AUTOSAR XML (schema 4-2-1)
package /DataType
  base type my_uint8: category=FIXED_LENGTH, base-type-size=8, base-type-encoding=NONE, native-declaration=unsigned char
  impl type my_uint8: category=VALUE, base-type=my_uint8, range phys 0..255, raw 0..255
  impl type CAN_FRAME: category=ARRAY
    element Array_Element: category=VALUE, array-size=8, array-size-handling=ALL-INDICES-SAME-ARRAY-SIZE, array-size-semantics=FIXED-SIZE, base-type=my_uint8, range phys 0..255, raw 0..255
package /Interfacing
  sender receiver interface SRI_CAN_Frame
    data CAN_Frame: type=CAN_FRAME, init-value=[0]
  sender receiver interface SRI_LED_Warning
    data LED_Warning: type=my_uint8, init-value=0
  client server interface CSI_Call_Subsystem
    operation Call_Subsystem: possible-error=[E_NOT_OK, E_OK]
      arg CAN_Frame: type=CAN_FRAME, direction=IN
    error E_NOT_OK: error-code=0
    error E_OK: error-code=1
  sender receiver interface SRI_LCD_Warning
    data LCD_Warning: type=my_uint8, init-value=0
  sender receiver interface SRI_Motor_Speed
    data Motor_Speed: type=my_uint8, init-value=0
package /SWCs
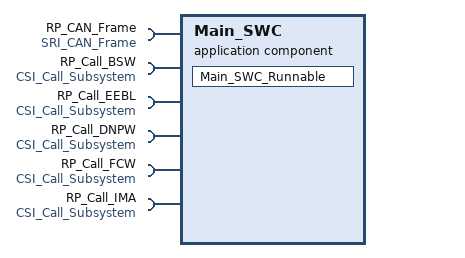
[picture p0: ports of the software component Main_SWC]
  application sw component type Main_SWC
    6 x require port:
      RP_CAN_Frame: required-interface=SRI_CAN_Frame
      RP_Call_BSW: required-interface=CSI_Call_Subsystem
      RP_Call_EEBL: required-interface=CSI_Call_Subsystem
      RP_Call_DNPW: required-interface=CSI_Call_Subsystem
      RP_Call_FCW: required-interface=CSI_Call_Subsystem
      RP_Call_IMA: required-interface=CSI_Call_Subsystem
    behavior IB_Main_SWC
      data received event Frame_Received_Event: start-on-event=Main_SWC_Runnable, data=CAN_Frame
      runnable Main_SWC_Runnable: symbol=Main_SWC
        data-read-access:
          access DR_Access: accessed-variable=RP_CAN_Frame.CAN_Frame
        5 x sync call:
          SYN_ServerCallDNPW: operation=RP_Call_DNPW.Call_Subsystem
          SYN_ServerCallFCW: operation=RP_Call_FCW.Call_Subsystem
          SYN_ServerCallBSW: operation=RP_Call_BSW.Call_Subsystem
          SYN_ServerCallIMA: operation=RP_Call_IMA.Call_Subsystem
          SYN_ServerCallEEBL: operation=RP_Call_EEBL.Call_Subsystem
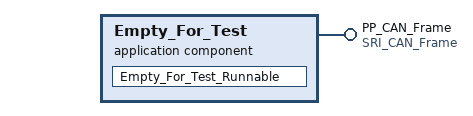
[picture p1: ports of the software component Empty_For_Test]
  application sw component type Empty_For_Test
    provide port PP_CAN_Frame: provided-interface=SRI_CAN_Frame
    behavior IB_Empty_For_Test
      runnable Empty_For_Test_Runnable: symbol=Empty_For_Test
        data-write-access:
          access DW_Access: accessed-variable=PP_CAN_Frame.CAN_Frame
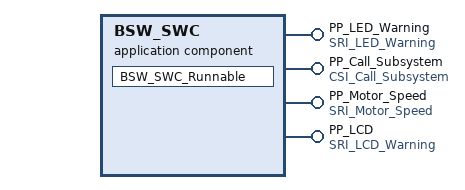
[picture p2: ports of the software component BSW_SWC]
  application sw component type BSW_SWC
    4 x provide port:
      PP_LED_Warning: provided-interface=SRI_LED_Warning
      PP_Call_Subsystem: provided-interface=CSI_Call_Subsystem
      PP_Motor_Speed: provided-interface=SRI_Motor_Speed
      PP_LCD: provided-interface=SRI_LCD_Warning
    behavior IB_BSW_SWC
      operation invoked event OIE_BSW_Runnable: start-on-event=BSW_SWC_Runnable, operation=PP_Call_Subsystem.Call_Subsystem
      runnable BSW_SWC_Runnable: symbol=BSW_SWC
        data-write-access:
          access DW_LED_Warning: accessed-variable=PP_LED_Warning.LED_Warning
          access DW_Motor_Speed: accessed-variable=PP_Motor_Speed.Motor_Speed
          access DW_LCD: accessed-variable=PP_LCD.LCD_Warning
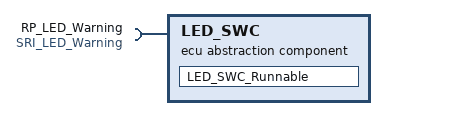
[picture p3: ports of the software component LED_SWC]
  ecu abstraction sw component type LED_SWC
    require port RP_LED_Warning: required-interface=SRI_LED_Warning
    behavior IB_LED_SWC
      data received event LED_Warning_Received_Event: start-on-event=LED_SWC_Runnable, data=LED_Warning
      runnable LED_SWC_Runnable: symbol=LED_SWC
        data-read-access:
          access DR_LED_Warning: accessed-variable=RP_LED_Warning.LED_Warning
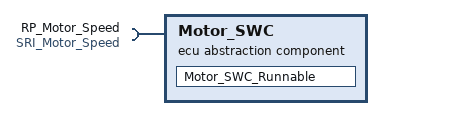
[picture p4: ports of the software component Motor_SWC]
  ecu abstraction sw component type Motor_SWC
    require port RP_Motor_Speed: required-interface=SRI_Motor_Speed
    behavior IB_Motor_Speed
      data received event Motor_Speed_Received_Event: start-on-event=Motor_SWC_Runnable, data=Motor_Speed
      runnable Motor_SWC_Runnable: symbol=Motor_SWC
        data-read-access:
          access DR_Motor_Speed: accessed-variable=RP_Motor_Speed.Motor_Speed
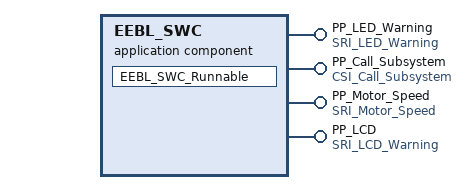
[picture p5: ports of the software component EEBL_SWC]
  application sw component type EEBL_SWC
    4 x provide port:
      PP_LED_Warning: provided-interface=SRI_LED_Warning
      PP_Call_Subsystem: provided-interface=CSI_Call_Subsystem
      PP_Motor_Speed: provided-interface=SRI_Motor_Speed
      PP_LCD: provided-interface=SRI_LCD_Warning
    behavior IB_EEBL_SWC
      operation invoked event OIE_EEBL_Runnable: start-on-event=EEBL_SWC_Runnable, operation=PP_Call_Subsystem.Call_Subsystem
      runnable EEBL_SWC_Runnable: symbol=BSW_SWC
        data-write-access:
          access DW_LED_Warning: accessed-variable=PP_LED_Warning.LED_Warning
          access DW_Motor_Speed: accessed-variable=PP_Motor_Speed.Motor_Speed
          access DW_LCD: accessed-variable=PP_LCD.LCD_Warning
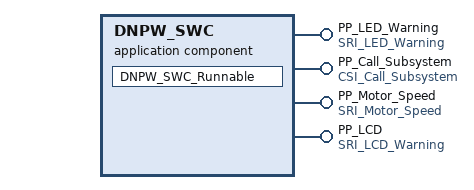
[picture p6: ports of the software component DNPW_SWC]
  application sw component type DNPW_SWC
    4 x provide port:
      PP_LED_Warning: provided-interface=SRI_LED_Warning
      PP_Call_Subsystem: provided-interface=CSI_Call_Subsystem
      PP_Motor_Speed: provided-interface=SRI_Motor_Speed
      PP_LCD: provided-interface=SRI_LCD_Warning
    behavior IB_DNPW_SWC
      operation invoked event OIE_DNPW_Runnable: start-on-event=DNPW_SWC_Runnable, operation=PP_Call_Subsystem.Call_Subsystem
      runnable DNPW_SWC_Runnable: symbol=DNPW_SWC
        data-write-access:
          access DW_LED_Warning: accessed-variable=PP_LED_Warning.LED_Warning
          access DW_Motor_Speed: accessed-variable=PP_Motor_Speed.Motor_Speed
          access DW_LCD: accessed-variable=PP_LCD.LCD_Warning
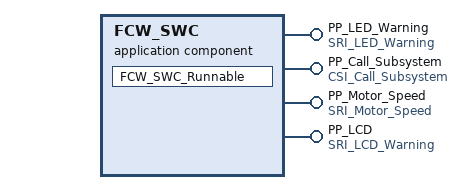
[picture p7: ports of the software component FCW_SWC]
  application sw component type FCW_SWC
    4 x provide port:
      PP_LED_Warning: provided-interface=SRI_LED_Warning
      PP_Call_Subsystem: provided-interface=CSI_Call_Subsystem
      PP_Motor_Speed: provided-interface=SRI_Motor_Speed
      PP_LCD: provided-interface=SRI_LCD_Warning
    behavior IB_FCW_SWC
      operation invoked event OIE_FCW_Runnable: start-on-event=FCW_SWC_Runnable, operation=PP_Call_Subsystem.Call_Subsystem
      runnable FCW_SWC_Runnable: symbol=FCW_SWC
        data-write-access:
          access DW_LED_Warning: accessed-variable=PP_LED_Warning.LED_Warning
          access DW_Motor_Speed: accessed-variable=PP_Motor_Speed.Motor_Speed
          access DW_LCD: accessed-variable=PP_LCD.LCD_Warning
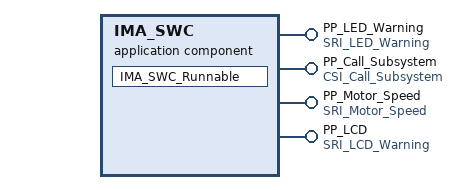
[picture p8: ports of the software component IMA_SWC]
  application sw component type IMA_SWC
    4 x provide port:
      PP_LED_Warning: provided-interface=SRI_LED_Warning
      PP_Call_Subsystem: provided-interface=CSI_Call_Subsystem
      PP_Motor_Speed: provided-interface=SRI_Motor_Speed
      PP_LCD: provided-interface=SRI_LCD_Warning
    behavior IB_IMA_SWC
      operation invoked event OIE_IMA_Runnable: start-on-event=IMA_SWC_Runnable, operation=PP_Call_Subsystem.Call_Subsystem
      runnable IMA_SWC_Runnable: symbol=IMA_SWC
        data-write-access:
          access DW_LED_Warning: accessed-variable=PP_LED_Warning.LED_Warning
          access DW_Motor_Speed: accessed-variable=PP_Motor_Speed.Motor_Speed
          access DW_LCD: accessed-variable=PP_LCD.LCD_Warning
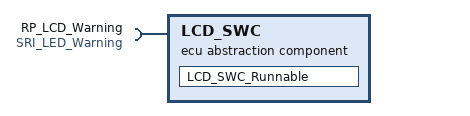
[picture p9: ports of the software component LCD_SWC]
  ecu abstraction sw component type LCD_SWC
    require port RP_LCD_Warning: required-interface=SRI_LED_Warning
    behavior IB_LCD_SWC
      data received event LCD_Warning_Received_Event: start-on-event=LCD_SWC_Runnable, data=LCD_Warning
      runnable LCD_SWC_Runnable: symbol=LCD_SWC
        data-read-access:
          access DR_LCD_Warning: accessed-variable=RP_LCD_Warning.LCD_Warning
package /Composition
  composition sw component type Composition_SWC
    10 x component:
      Main_SWC: type=Main_SWC
      Empty_For_Test: type=Empty_For_Test
      LED_SWC: type=LED_SWC
      BSW_SWC: type=BSW_SWC
      Motor_SWC: type=Motor_SWC
      EEBL_SWC: type=EEBL_SWC
      DNPW_SWC: type=DNPW_SWC
      FCW_SWC: type=FCW_SWC
      IMA_SWC: type=IMA_SWC
      LCD_SWC: type=LCD_SWC
    connect Empty_For_Test.PP_CAN_Frame -> Main_SWC.RP_CAN_Frame
    connect BSW_SWC.PP_Call_Subsystem -> Main_SWC.RP_Call_BSW
    connect EEBL_SWC.PP_Call_Subsystem -> Main_SWC.RP_Call_EEBL
    connect DNPW_SWC.PP_Call_Subsystem -> Main_SWC.RP_Call_DNPW
    connect FCW_SWC.PP_Call_Subsystem -> Main_SWC.RP_Call_FCW
    connect IMA_SWC.PP_Call_Subsystem -> Main_SWC.RP_Call_IMA
    connect BSW_SWC.PP_LCD -> LCD_SWC.RP_LCD_Warning
    connect FCW_SWC.PP_LCD -> LCD_SWC.RP_LCD_Warning
    connect IMA_SWC.PP_LCD -> LCD_SWC.RP_LCD_Warning
    connect DNPW_SWC.PP_LCD -> LCD_SWC.RP_LCD_Warning
    connect EEBL_SWC.PP_LCD -> LCD_SWC.RP_LCD_Warning
    connect BSW_SWC.PP_LED_Warning -> LED_SWC.RP_LED_Warning
    connect FCW_SWC.PP_LED_Warning -> LED_SWC.RP_LED_Warning
    connect IMA_SWC.PP_LED_Warning -> LED_SWC.RP_LED_Warning
    connect DNPW_SWC.PP_LED_Warning -> LED_SWC.RP_LED_Warning
    connect EEBL_SWC.PP_LED_Warning -> LED_SWC.RP_LED_Warning
    connect BSW_SWC.PP_Motor_Speed -> Motor_SWC.RP_Motor_Speed
    connect FCW_SWC.PP_Motor_Speed -> Motor_SWC.RP_Motor_Speed
    connect IMA_SWC.PP_Motor_Speed -> Motor_SWC.RP_Motor_Speed
    connect DNPW_SWC.PP_Motor_Speed -> Motor_SWC.RP_Motor_Speed
    connect EEBL_SWC.PP_Motor_Speed -> Motor_SWC.RP_Motor_Speed
